# cross_trigger_network: IP-XACT component
VLNV tenstorrent.com:ocah:cross_trigger_network:1.0

## Address spaces and blocks
cross_trigger_network_mmap.cross_trigger_network: base 'h0, range 'h300, width 32

## Registers
Registers are 32-bit, read-write, reset 0x0 unless marked. A register's access mark holds for its fields unless they carry their own. Offsets are from the block's base; lines under a group give offsets from that group; [hi:lo] are bit positions; {n}, {i} and the like mark numbered series; 'fields as' and 'values as' point back to an identical list; <NAME> marks a mode.

## cross_trigger_network_mmap.cross_trigger_network — Cross trigger matrix and externally visible cross trigger ports
Base 0x00000000
0x00 ctm group — Configuration registers for the cross trigger matrix
  {0x0+8j} CT_SRC[{j}] (j=0..25) group — Cross trigger destination selection for one CT_Src output port
    0x00 CONFIG_0 — Cross Trigger Source Configuration - CT_Dst select mask
      [25:0] CT_DST_SELECT — Selects the CT_Dst port(s) to forward on the CT_Src output at this array index. Each bit corresponds to one CT_Dst port, from CT_Dst[0] at bit 0 upwards. Multiple ports may be selected as a trigger source. All selected source ports are then OR'd together to produce the CT_Src output. Set this register to all-zero to disable that output.
{0x200+0x10*i} ctp[{i}] (i=0..15) group — Configuration and status registers for the cross trigger port
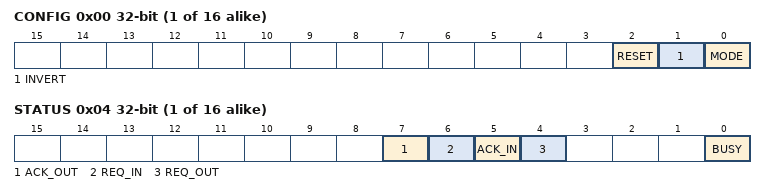
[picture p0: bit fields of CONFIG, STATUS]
  0x00 CONFIG — Cross Trigger Port Configuration
    [2] RESET — While set, holds the outgoing point-to-point handshake idle with CT_Req_out deasserted and discards core-side cross trigger pulses for transmission. The incoming handshake keeps running. Set and then clear it to recover a handshake deadlock.
    [1] INVERT — Inverts the sense of the incoming and outgoing GPIO signals. 0 - No inversion. Wire-OR mode uses active-low signaling with active or passive pull-ups. Point-to-point mode uses active-high signaling. 1 - All inputs and outputs of I/Os are inverted. Wire-OR mode uses active-high signaling with active or passive pull-downs. Point-to-point mode uses active-low signaling. Write it in the same access as MODE.
    [0] MODE — Selects the operating mode of the CTP. 0 - Wire-OR, 1 - Point-to-Point. Program it once, in the same write as INVERT, from the package's cross trigger topology, before any cross trigger matrix route selects or targets this port. While wire-OR is selected the point-to-point handshake is held idle with its request deasserted; after point-to-point is selected, the handshake ignores the CT_Req_in and CT_Ack_in pads until their synchronized levels are valid.
  0x04 STATUS ro — Cross Trigger Port Status. Writes complete with an OKAY response and leave the register unchanged.
    [7] ACK_OUT — Readout of the current CT_Ack_out level with CONFIG.INVERT undone, so 1 means the acknowledge is asserted whatever the pad polarity. Reads 0 in wire-OR mode.
    [6] REQ_IN — Readout of the current synchronized CT_Req_in level with CONFIG.INVERT undone, so 1 means the request is asserted whatever the pad polarity.
    [5] ACK_IN — Readout of the current synchronized CT_Ack_in level with CONFIG.INVERT undone, so 1 means the acknowledge is asserted whatever the pad polarity.
    [4] REQ_OUT — Readout of the current CT_Req_out level with CONFIG.INVERT undone, so 1 means the request is asserted whatever the pad polarity. Reads 0 in wire-OR mode.
    [0] BUSY — Indicates whether a pulse assertion or handshake is currently in progress. 0 - Pulse or handshake is not in progress, 1 - Pulse or handshake is currently in progress
  0x08 STRETCH_MULT — Pulse Stretch Multiplier
    [15:0] STRETCH_MULT — The number of clock cycles a core-side cross trigger pulse is stretched on the GPIO pin when in wire-OR mode. Whenever a core-side pulse is received, the generated GPIO pulse has a width of (STRETCH_MULT+1) clock cycles.

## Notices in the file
SPDX-License-Identifier: Apache-2.0
SPDX-FileCopyrightText: 2026 Tenstorrent USA, Inc.
